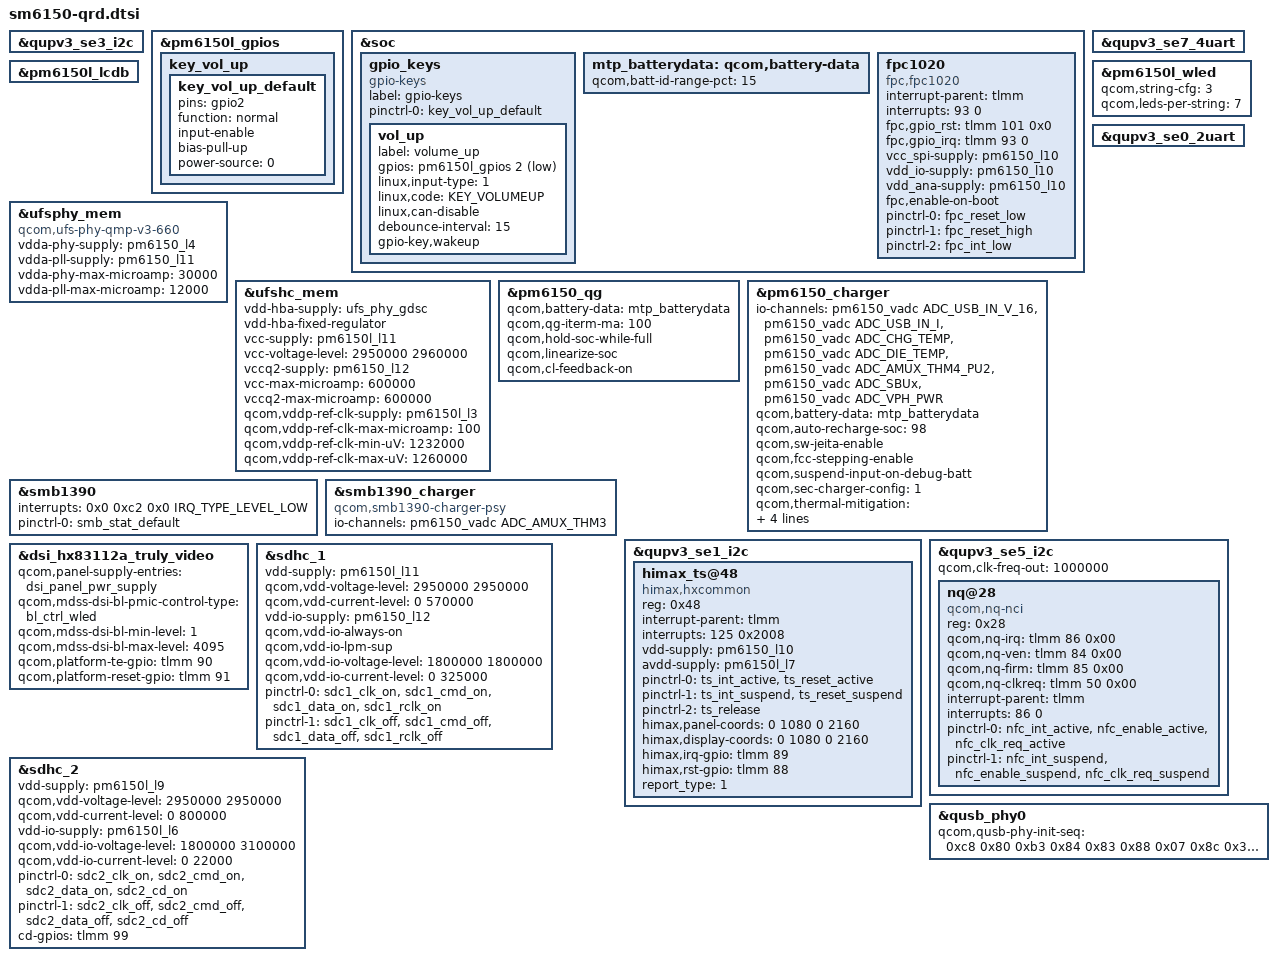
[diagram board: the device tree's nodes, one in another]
/* Copyright (c) 2018, The Linux Foundation. All rights reserved.
 *
 * This program is free software; you can redistribute it and/or modify
 * it under the terms of the GNU General Public License version 2 and
 * only version 2 as published by the Free Software Foundation.
 *
 * This program is distributed in the hope that it will be useful,
 * but WITHOUT ANY WARRANTY; without even the implied warranty of
 * MERCHANTABILITY or FITNESS FOR A PARTICULAR PURPOSE.  See the
 * GNU General Public License for more details.
 */

#include "sm6150-thermal-overlay.dtsi"
#include <dt-bindings/gpio/gpio.h>
#include <dt-bindings/iio/qcom,spmi-vadc.h>
#include <dt-bindings/input/input.h>
#include "sm6150-sde-display.dtsi"
#include "sm6150-camera-sensor-qrd.dtsi"

&qupv3_se3_i2c {
	status = "ok";
	#include "smb1390.dtsi"
	#include "smb1355.dtsi"
};

&pm6150l_gpios {
	key_vol_up {
		key_vol_up_default: key_vol_up_default {
			pins = "gpio2";
			function = "normal";
			input-enable;
			bias-pull-up;
			power-source = <0>;
		};
	};
};

&soc {
	gpio_keys {
		compatible = "gpio-keys";
		label = "gpio-keys";

		pinctrl-names = "default";
		pinctrl-0 = <&key_vol_up_default>;

		vol_up {
			label = "volume_up";
			gpios = <&pm6150l_gpios 2 GPIO_ACTIVE_LOW>;
			linux,input-type = <1>;
			linux,code = <KEY_VOLUMEUP>;
			linux,can-disable;
			debounce-interval = <15>;
			gpio-key,wakeup;
		};
	};

	mtp_batterydata: qcom,battery-data {
		qcom,batt-id-range-pct = <15>;
		#include "qg-batterydata-alium-3600mah.dtsi"
		#include "qg-batterydata-mlp356477-2800mah.dtsi"
	};
};

&qupv3_se7_4uart {
	status = "ok";
};

&pm6150l_wled {
	qcom,string-cfg= <3>;
	qcom,leds-per-string = <7>;
	status = "ok";
};

&pm6150l_lcdb {
	status = "ok";
};

&qupv3_se0_2uart {
	status = "ok";
};

&ufsphy_mem {
	compatible = "qcom,ufs-phy-qmp-v3-660";

	vdda-phy-supply = <&pm6150_l4>; /* 0.9v */
	vdda-pll-supply = <&pm6150_l11>;
	vdda-phy-max-microamp = <30000>;
	vdda-pll-max-microamp = <12000>;

	status = "ok";
};

&ufshc_mem {
	vdd-hba-supply = <&ufs_phy_gdsc>;
	vdd-hba-fixed-regulator;
	vcc-supply = <&pm6150l_l11>;
	vcc-voltage-level = <2950000 2960000>;
	vccq2-supply = <&pm6150_l12>;
	vcc-max-microamp = <600000>;
	vccq2-max-microamp = <600000>;

	qcom,vddp-ref-clk-supply = <&pm6150l_l3>;
	qcom,vddp-ref-clk-max-microamp = <100>;
	qcom,vddp-ref-clk-min-uV = <1232000>;
	qcom,vddp-ref-clk-max-uV = <1260000>;

	status = "ok";
};

&pm6150_qg {
	qcom,battery-data = <&mtp_batterydata>;
	qcom,qg-iterm-ma = <100>;
	qcom,hold-soc-while-full;
	qcom,linearize-soc;
	qcom,cl-feedback-on;
};

&pm6150_charger {
	io-channels = <&pm6150_vadc ADC_USB_IN_V_16>,
		      <&pm6150_vadc ADC_USB_IN_I>,
		      <&pm6150_vadc ADC_CHG_TEMP>,
		      <&pm6150_vadc ADC_DIE_TEMP>,
		      <&pm6150_vadc ADC_AMUX_THM4_PU2>,
		      <&pm6150_vadc ADC_SBUx>,
		      <&pm6150_vadc ADC_VPH_PWR>;
	io-channel-names = "usb_in_voltage",
			   "usb_in_current",
			   "chg_temp",
			   "die_temp",
			   "conn_temp",
			   "sbux_res",
			   "vph_voltage";
	qcom,battery-data = <&mtp_batterydata>;
	qcom,auto-recharge-soc = <98>;
	qcom,sw-jeita-enable;
	qcom,fcc-stepping-enable;
	qcom,suspend-input-on-debug-batt;
	qcom,sec-charger-config = <1>;
	qcom,thermal-mitigation = <4200000 3500000 3000000
			2500000 2000000 1500000 1000000 500000>;
	dpdm-supply = <&qusb_phy0>;
	qcom,charger-temp-max = <800>;
	qcom,smb-temp-max = <800>;
};

&smb1390 {
	/delete-property/ interrupts;
	interrupts = <0x0 0xc2 0x0 IRQ_TYPE_LEVEL_LOW>;
	pinctrl-names = "default";
	pinctrl-0 = <&smb_stat_default>;
	status = "ok";
};

&smb1390_charger {
	/delete-property/ compatible;
	compatible = "qcom,smb1390-charger-psy";
	io-channels = <&pm6150_vadc ADC_AMUX_THM3>;
	io-channel-names = "cp_die_temp";
	status = "ok";
};

&qupv3_se1_i2c {
	status = "okay";
	himax_ts@48 {
		compatible = "himax,hxcommon";
		reg = <0x48>;
		interrupt-parent = <&tlmm>;
		interrupts = <125 0x2008>;
		vdd-supply = <&pm6150_l10>;
		avdd-supply = <&pm6150l_l7>;
		pinctrl-names = "pmx_ts_active","pmx_ts_suspend",
					"pmx_ts_release";
		pinctrl-0 = <&ts_int_active &ts_reset_active>;
		pinctrl-1 = <&ts_int_suspend &ts_reset_suspend>;
		pinctrl-2 = <&ts_release>;
		himax,panel-coords = <0 1080 0 2160>;
		himax,display-coords = <0 1080 0 2160>;
		himax,irq-gpio = <&tlmm 89 0x00>;
		himax,rst-gpio = <&tlmm 88 0x00>;
		report_type = <1>;
	};
};

&qupv3_se5_i2c {
	status = "ok";
	qcom,clk-freq-out = <1000000>;
	nq@28 {
		compatible = "qcom,nq-nci";
		reg = <0x28>;
		qcom,nq-irq = <&tlmm 86 0x00>;
		qcom,nq-ven = <&tlmm 84 0x00>;
		qcom,nq-firm = <&tlmm 85 0x00>;
		qcom,nq-clkreq = <&tlmm 50 0x00>;
		interrupt-parent = <&tlmm>;
		interrupts = <86 0>;
		interrupt-names = "nfc_irq";
		pinctrl-names = "nfc_active", "nfc_suspend";
		pinctrl-0 = <&nfc_int_active &nfc_enable_active
				&nfc_clk_req_active>;
		pinctrl-1 = <&nfc_int_suspend &nfc_enable_suspend
				&nfc_clk_req_suspend>;
	};
};

&dsi_hx83112a_truly_video {
	qcom,panel-supply-entries = <&dsi_panel_pwr_supply>;
	qcom,mdss-dsi-bl-pmic-control-type = "bl_ctrl_wled";
	qcom,mdss-dsi-bl-min-level = <1>;
	qcom,mdss-dsi-bl-max-level = <4095>;
	qcom,platform-te-gpio = <&tlmm 90 0>;
	qcom,platform-reset-gpio = <&tlmm 91 0>;
};

&sdhc_1 {
	vdd-supply = <&pm6150l_l11>;
	qcom,vdd-voltage-level = <2950000 2950000>;
	qcom,vdd-current-level = <0 570000>;

	vdd-io-supply = <&pm6150_l12>;
	qcom,vdd-io-always-on;
	qcom,vdd-io-lpm-sup;
	qcom,vdd-io-voltage-level = <1800000 1800000>;
	qcom,vdd-io-current-level = <0 325000>;

	pinctrl-names = "active", "sleep";
	pinctrl-0 = <&sdc1_clk_on &sdc1_cmd_on &sdc1_data_on &sdc1_rclk_on>;
	pinctrl-1 = <&sdc1_clk_off &sdc1_cmd_off &sdc1_data_off &sdc1_rclk_off>;

	status = "ok";
};

&sdhc_2 {
	vdd-supply = <&pm6150l_l9>;
	qcom,vdd-voltage-level = <2950000 2950000>;
	qcom,vdd-current-level = <0 800000>;

	vdd-io-supply = <&pm6150l_l6>;
	qcom,vdd-io-voltage-level = <1800000 3100000>;
	qcom,vdd-io-current-level = <0 22000>;

	pinctrl-names = "active", "sleep";
	pinctrl-0 = <&sdc2_clk_on  &sdc2_cmd_on &sdc2_data_on &sdc2_cd_on>;
	pinctrl-1 = <&sdc2_clk_off &sdc2_cmd_off &sdc2_data_off &sdc2_cd_off>;

	cd-gpios = <&tlmm 99 0>;

	status = "ok";
};

&soc {
	fpc1020 {
		compatible = "fpc,fpc1020";
		interrupt-parent = <&tlmm>;
		interrupts = <93 0>;
		fpc,gpio_rst = <&tlmm 101 0x0>;
		fpc,gpio_irq = <&tlmm 93 0>;
		vcc_spi-supply = <&pm6150_l10>;
		vdd_io-supply  = <&pm6150_l10>;
		vdd_ana-supply = <&pm6150_l10>;
		fpc,enable-on-boot;
		pinctrl-names = "fpc1020_reset_reset",
				"fpc1020_reset_active",
				"fpc1020_irq_active";
		pinctrl-0 = <&fpc_reset_low>;
		pinctrl-1 = <&fpc_reset_high>;
		pinctrl-2 = <&fpc_int_low>;
	};

};

/* Primary USB port related High Speed PHY */
&qusb_phy0 {
	qcom,qusb-phy-init-seq = <0xc8 0x80
				0xb3 0x84
				0x83 0x88
				0x07 0x8c
				0x30 0x08
				0x79 0x0c
				0x21 0x10
				0x14 0x9c
				0x9f 0x1c
				0x00 0x18>;
};
